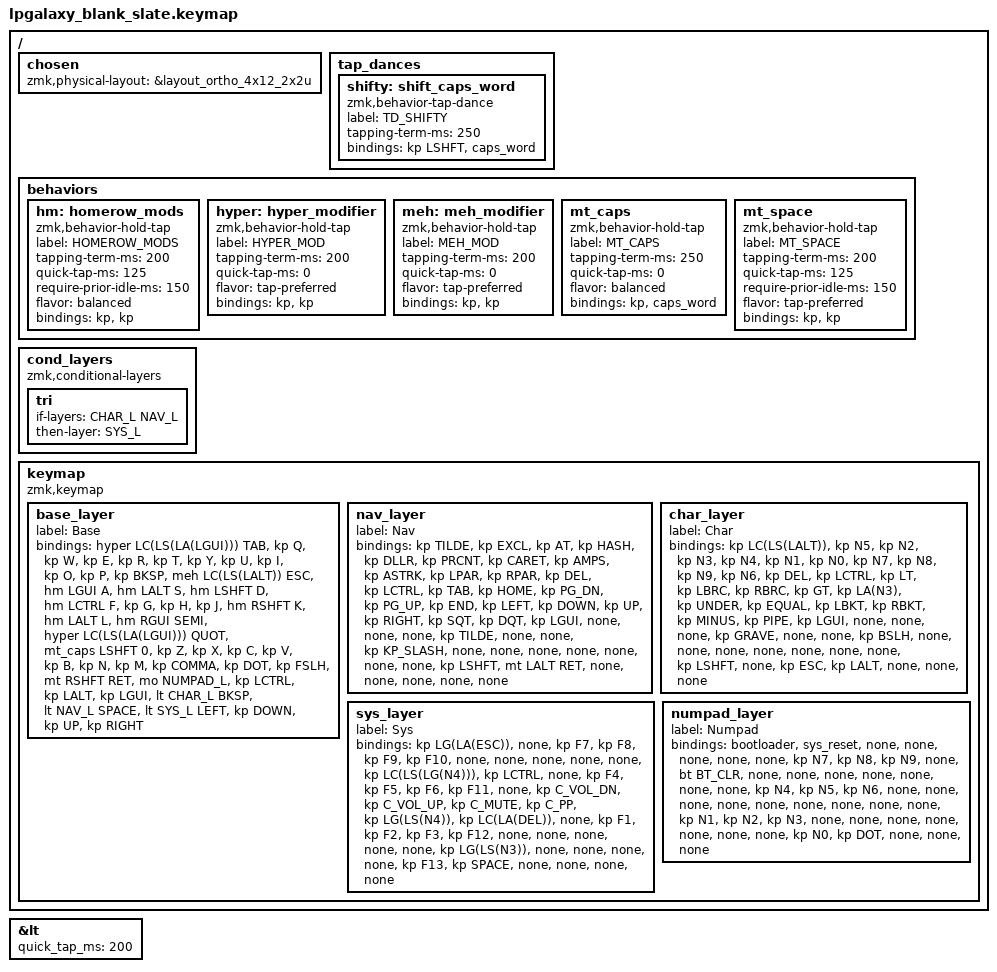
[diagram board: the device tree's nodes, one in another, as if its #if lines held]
/*
 * Copyright (c) 2022 Pete Johanson
 *
 * SPDX-License-Identifier: MIT
 */

#include <behaviors.dtsi>
#include <dt-bindings/zmk/keys.h>
#include <dt-bindings/zmk/bt.h>
#include <dt-bindings/zmk/outputs.h>

#define QWERTY_BASE 1

#define TBLE_ORTHO   1
// #define TBLE_MIT     1
// #define TBLE_DUAL_2U 1

#define NAV_L 1
#define CHAR_L 2
#define SYS_L 3
#define NUMPAD_L 4

// Using layer taps on thumbs, having quick tap as well helps w/ repeating space/backspace
&lt { quick_tap_ms = <200>; };

#define BT(n) BT_SEL n

/ {
    chosen {
       zmk,physical-layout =
#ifdef TBLE_DUAL_2U
                       &layout_ortho_4x12_2x2u;
#elif defined(TBLE_MIT)
                       &layout_ortho_4x12_1x2u;
#else
                       &layout_ortho_4x12_all1u;
#endif
    };

    tap_dances {
    	shifty: shift_caps_word {
        compatible = "zmk,behavior-tap-dance";
        label = "TD_SHIFTY";
        #binding-cells = <0>;
        tapping-term-ms = <250>;
        bindings = <&kp LSHFT>, <&caps_word>;
      };
    };

    behaviors {
        // Home row mods with require-prior-idle to prevent accidental activation during fast typing
        hm: homerow_mods {
            compatible = "zmk,behavior-hold-tap";
            label = "HOMEROW_MODS";
            #binding-cells = <2>;
            tapping-term-ms = <200>;
            quick-tap-ms = <125>;
            require-prior-idle-ms = <150>;
            flavor = "balanced";
            bindings = <&kp>, <&kp>;
        };

        // Hyper modifier (Ctrl+Shift+Alt+GUI) when held, key when tapped
        hyper: hyper_modifier {
            compatible = "zmk,behavior-hold-tap";
            label = "HYPER_MOD";
            #binding-cells = <2>;
            tapping-term-ms = <200>;
            quick-tap-ms = <0>;
            flavor = "tap-preferred";
            bindings = <&kp>, <&kp>;
        };

        // Meh modifier (Ctrl+Shift+Alt) when held, key when tapped
        meh: meh_modifier {
            compatible = "zmk,behavior-hold-tap";
            label = "MEH_MOD";
            #binding-cells = <2>;
            tapping-term-ms = <200>;
            quick-tap-ms = <0>;
            flavor = "tap-preferred";
            bindings = <&kp>, <&kp>;
        };

        // Capslock 
        mt_caps: mt_caps {
            compatible = "zmk,behavior-hold-tap";
            label = "MT_CAPS";
            #binding-cells = <2>;
            tapping-term-ms = <250>;
            quick-tap-ms = <0>;
            flavor = "balanced";
            bindings = <&kp>, <&caps_word>;
        };

        // Space/Control mod-tap tuned for fast typing (more affirmative holds)
        mt_space: mt_space {
            compatible = "zmk,behavior-hold-tap";
            label = "MT_SPACE";
            #binding-cells = <2>;
            tapping-term-ms = <200>;
            quick-tap-ms = <125>;
            require-prior-idle-ms = <150>;
            flavor = "tap-preferred";
            bindings = <&kp>, <&kp>;
        };
    };

// Conditional layer only when we have less thumb keys
#ifdef TBLE_DUAL_2U
    cond_layers {
        compatible = "zmk,conditional-layers";
	tri {
	    if-layers = <CHAR_L NAV_L>;
	    then-layer = <SYS_L>;
        };
    };
#endif

    keymap {
        compatible = "zmk,keymap";

        base_layer {
            label = "Base";
            bindings = <
// Ported from QMK drop_planck7.json layer 0
 &hyper LC(LS(LA(LGUI))) TAB  &kp Q         &kp W         &kp E         &kp R         &kp T         &kp Y         &kp U         &kp I         &kp O         &kp P         &kp BKSP
 &meh LC(LS(LALT)) ESC        &hm LGUI A    &hm LALT S    &hm LSHFT D   &hm LCTRL F   &kp G         &kp H         &kp J         &hm RSHFT K   &hm LALT L    &hm RGUI SEMI &hyper LC(LS(LA(LGUI))) QUOT
 &mt_caps LSHFT 0             &kp Z         &kp X         &kp C         &kp V         &kp B         &kp N         &kp M         &kp COMMA     &kp DOT       &kp FSLH      &mt RSHFT RET
#ifdef TBLE_DUAL_2U
 &mo NUMPAD_L   &kp LCTRL   &kp LALT   &kp LGUI   &lt CHAR_L BKSP   &lt NAV_L SPACE   &lt SYS_L LEFT   &kp DOWN      &kp UP        &kp RIGHT
#elif defined(TBLE_MIT)
 &mo NUMPAD_L   &kp LCTRL   &kp LALT   &kp LGUI   &lt CHAR_L BKSP   &mt_space LCTRL SPACE   &mo NAV_L      &lt SYS_L LEFT   &kp DOWN     &kp UP       &kp RIGHT
#else
 &mo NUMPAD_L   &kp LCTRL   &kp LALT   &kp LGUI   &lt CHAR_L BKSP   &mt_space LCTRL SPACE   &mt_space LCTRL SPACE   &mo NAV_L     &lt SYS_L LEFT   &kp DOWN     &kp UP       &kp RIGHT
#endif
            >;
        };

        nav_layer {
            label = "Nav";
            bindings = <
// Ported from QMK layer 3 (Nav + Symbols)
&kp TILDE  &kp EXCL  &kp AT    &kp HASH  &kp DLLR  &kp PRCNT    &kp CARET  &kp AMPS      &kp ASTRK    &kp LPAR   &kp RPAR   &kp DEL
&kp LCTRL  &kp TAB   &kp HOME  &kp PG_DN &kp PG_UP &kp END      &kp LEFT   &kp DOWN      &kp UP       &kp RIGHT  &kp SQT    &kp DQT
&kp LGUI   &none     &none     &none     &kp TILDE &none        &none      &kp KP_SLASH  &none        &none      &none      &none
#ifdef TBLE_DUAL_2U
&none      &none     &none     &kp LSHFT   &mt LALT RET   &none     &none     &none     &none     &none
#elif defined(TBLE_MIT)
&none      &none     &none     &kp LSHFT   &kp LALT       &kp RET   &none     &none     &none     &none     &none
#else
&none      &none     &none     &kp LSHFT   &kp LALT       &kp RET        &kp RET        &none     &none     &none     &none     &none
#endif
            >;
        };

        char_layer {
            label = "Char";
            bindings = <
// Ported from QMK layer 4 (Num + Operators) - custom number layout
&kp LC(LS(LALT))  &kp N5    &kp N2    &kp N3    &kp N4    &kp N1      &kp N0      &kp N7      &kp N8      &kp N9      &kp N6      &kp DEL
&kp LCTRL         &kp LT    &kp LBRC  &kp RBRC  &kp GT    &kp LA(N3)  &kp UNDER   &kp EQUAL   &kp LBKT    &kp RBKT    &kp MINUS   &kp PIPE
&kp LGUI          &none     &none     &none     &kp GRAVE &none       &none       &kp BSLH    &none       &none       &none       &none
#ifdef TBLE_DUAL_2U
&none              &none     &none     &kp LSHFT   &none            &kp ESC   &kp LALT   &none     &none     &none
#elif defined(TBLE_MIT)
&none              &none     &none     &kp LSHFT   &none            &kp ESC   &kp LALT   &none     &none     &none     &none
#else
&none              &none     &none     &kp LSHFT   &none            &kp ESC      &kp ESC      &kp LALT   &none     &none     &none     &none
#endif
            >;
        };

        sys_layer {
            label = "Sys";
            bindings = <
// Ported from QMK layer 5 (System + Function keys)
&kp LG(LA(ESC))  &none    &kp F7  &kp F8  &kp F9  &kp F10   &none         &none         &none         &none         &none       &kp LC(LS(LG(N4)))
&kp LCTRL        &none    &kp F4  &kp F5  &kp F6  &kp F11   &none         &kp C_VOL_DN  &kp C_VOL_UP  &kp C_MUTE    &kp C_PP    &kp LG(LS(N4))
&kp LC(LA(DEL))  &none    &kp F1  &kp F2  &kp F3  &kp F12   &none         &none         &none         &none         &none       &kp LG(LS(N3))
#ifdef TBLE_DUAL_2U
&none    &none     &none     &none     &kp F13     &kp SPACE   &none  &none  &none  &none
#elif defined(TBLE_MIT)
&none    &none     &none     &none     &kp F13     &kp SPACE   &kp LG(LS(N5))  &none  &none  &none  &none
#else
&none    &none     &none     &none     &kp F13     &kp SPACE   &kp SPACE       &kp LG(LS(N5))  &none  &none  &none  &none
#endif
            >;
        };

        numpad_layer {
            label = "Numpad";
            bindings = <
// Number pad using top-row digit HID codes (N*, not KP_*) so they always type
// digits regardless of host Num Lock. BT profile selection dropped — metal chassis blocks signal.
&bootloader  &sys_reset  &none  &none  &none  &none  &none  &kp N7  &kp N8  &kp N9  &none  &bt BT_CLR
&none  &none  &none  &none  &none  &none  &none  &kp N4  &kp N5  &kp N6  &none  &none
&none  &none  &none  &none  &none  &none  &none  &kp N1  &kp N2  &kp N3  &none  &none
#ifdef TBLE_DUAL_2U
&none  &none  &none  &none  &none  &kp N0  &kp DOT  &none  &none  &none
#elif defined(TBLE_MIT)
&none  &none  &none  &none  &none  &none  &kp N0  &kp DOT  &none  &none  &none
#else
&none  &none  &none  &none  &none  &none  &none  &kp N0  &kp DOT  &none  &none  &none
#endif
            >;
        };


    };
};
